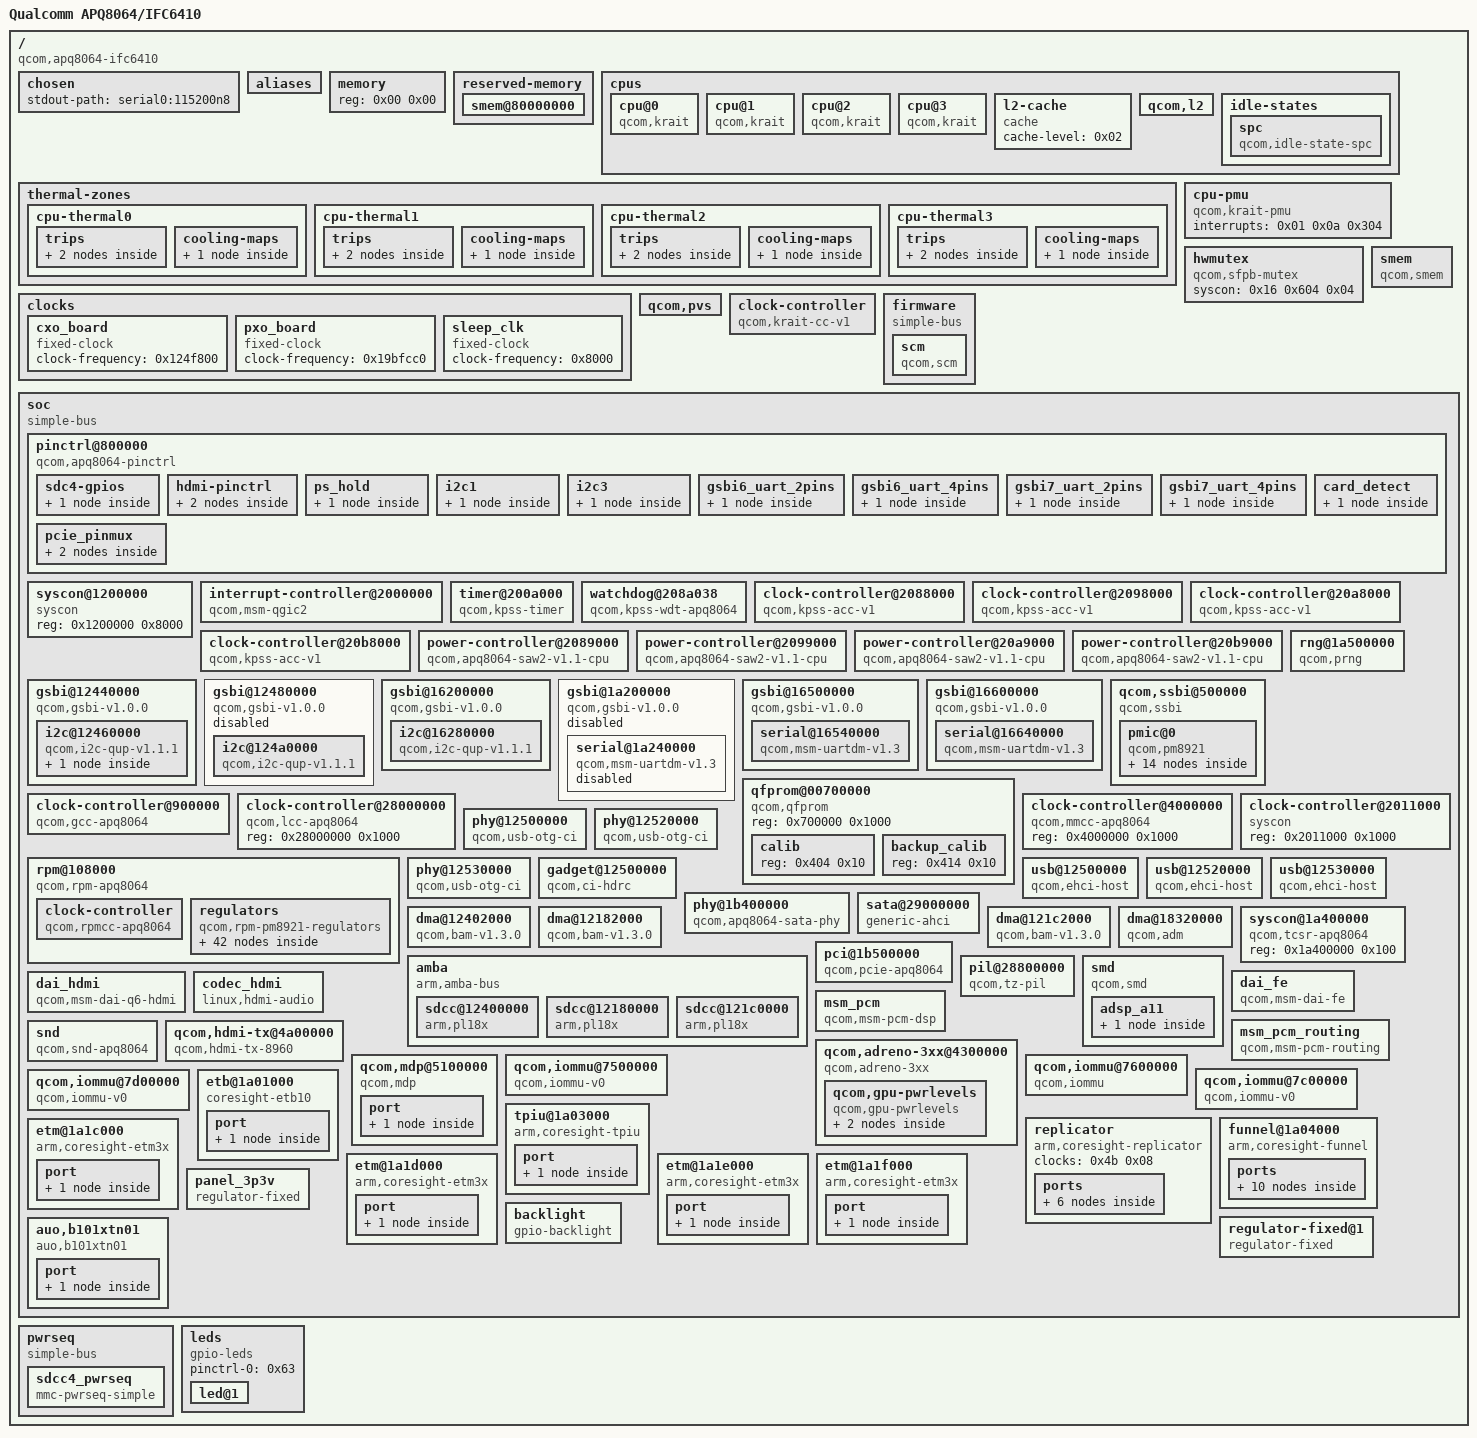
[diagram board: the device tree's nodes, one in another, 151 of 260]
/dts-v1/;

/ {
	#address-cells = <0x01>;
	#size-cells = <0x01>;
	model = "Qualcomm APQ8064/IFC6410";
	compatible = "qcom,apq8064-ifc6410\0qcom,apq8064";
	interrupt-parent = <0x01>;

	chosen {
		stdout-path = "serial0:115200n8";
	};

	aliases {
		serial0 = "/soc/gsbi@16600000/serial@16640000";
		serial1 = "/soc/gsbi@16500000/serial@16540000";
	};

	memory {
		device_type = "memory";
		reg = <0x00 0x00>;
	};

	reserved-memory {
		#address-cells = <0x01>;
		#size-cells = <0x01>;
		ranges;

		smem@80000000 {
			reg = <0x80000000 0x200000>;
			no-map;
			linux,phandle = <0x17>;
			phandle = <0x17>;
		};
	};

	cpus {
		#address-cells = <0x01>;
		#size-cells = <0x00>;

		cpu@0 {
			compatible = "qcom,krait";
			enable-method = "qcom,kpss-acc-v1";
			device_type = "cpu";
			reg = <0x00>;
			next-level-cache = <0x02>;
			qcom,acc = <0x03>;
			qcom,saw = <0x04>;
			cpu-idle-states = <0x05>;
			clocks = <0x06 0x00 0x06 0x04>;
			clock-names = "cpu\0l2";
			clock-latency = <0x186a0>;
			cooling-min-level = <0x00>;
			cooling-max-level = <0x07>;
			#cooling-cells = <0x02>;
			cpu-supply = <0x04>;
			linux,phandle = <0x0f>;
			phandle = <0x0f>;
		};

		cpu@1 {
			compatible = "qcom,krait";
			enable-method = "qcom,kpss-acc-v1";
			device_type = "cpu";
			reg = <0x01>;
			next-level-cache = <0x02>;
			qcom,acc = <0x07>;
			qcom,saw = <0x08>;
			cpu-idle-states = <0x05>;
			clocks = <0x06 0x01 0x06 0x04>;
			clock-names = "cpu\0l2";
			clock-latency = <0x186a0>;
			cooling-min-level = <0x00>;
			cooling-max-level = <0x07>;
			#cooling-cells = <0x02>;
			cpu-supply = <0x08>;
			linux,phandle = <0x11>;
			phandle = <0x11>;
		};

		cpu@2 {
			compatible = "qcom,krait";
			enable-method = "qcom,kpss-acc-v1";
			device_type = "cpu";
			reg = <0x02>;
			next-level-cache = <0x02>;
			qcom,acc = <0x09>;
			qcom,saw = <0x0a>;
			cpu-idle-states = <0x05>;
			clocks = <0x06 0x02 0x06 0x04>;
			clock-names = "cpu\0l2";
			clock-latency = <0x186a0>;
			cooling-min-level = <0x00>;
			cooling-max-level = <0x07>;
			#cooling-cells = <0x02>;
			cpu-supply = <0x0a>;
			linux,phandle = <0x13>;
			phandle = <0x13>;
		};

		cpu@3 {
			compatible = "qcom,krait";
			enable-method = "qcom,kpss-acc-v1";
			device_type = "cpu";
			reg = <0x03>;
			next-level-cache = <0x02>;
			qcom,acc = <0x0b>;
			qcom,saw = <0x0c>;
			cpu-idle-states = <0x05>;
			clocks = <0x06 0x03 0x06 0x04>;
			clock-names = "cpu\0l2";
			clock-latency = <0x186a0>;
			cooling-min-level = <0x00>;
			cooling-max-level = <0x07>;
			#cooling-cells = <0x02>;
			cpu-supply = <0x0c>;
			linux,phandle = <0x15>;
			phandle = <0x15>;
		};

		l2-cache {
			compatible = "cache";
			cache-level = <0x02>;
			linux,phandle = <0x02>;
			phandle = <0x02>;
		};

		qcom,l2 {
			qcom,l2-rates = <0x16e36000 0x39ef8b00 0x46cf7100>;
		};

		idle-states {

			spc {
				compatible = "qcom,idle-state-spc\0arm,idle-state";
				entry-latency-us = <0x190>;
				exit-latency-us = <0x384>;
				min-residency-us = <0xbb8>;
				linux,phandle = <0x05>;
				phandle = <0x05>;
			};
		};
	};

	thermal-zones {

		cpu-thermal0 {
			polling-delay-passive = <0xfa>;
			polling-delay = <0x3e8>;
			thermal-sensors = <0x0d 0x07>;

			trips {

				trip@0 {
					temperature = <0x124f8>;
					hysteresis = <0x7d0>;
					type = "passive";
					linux,phandle = <0x0e>;
					phandle = <0x0e>;
				};

				trip@1 {
					temperature = <0x17318>;
					hysteresis = <0x7d0>;
					type = "critical";
				};
			};

			cooling-maps {

				map0 {
					trip = <0x0e>;
					cooling-device = <0x0f 0xffffffff 0xffffffff>;
				};
			};
		};

		cpu-thermal1 {
			polling-delay-passive = <0xfa>;
			polling-delay = <0x3e8>;
			thermal-sensors = <0x0d 0x08>;

			trips {

				trip@0 {
					temperature = <0x124f8>;
					hysteresis = <0x7d0>;
					type = "passive";
					linux,phandle = <0x10>;
					phandle = <0x10>;
				};

				trip@1 {
					temperature = <0x17318>;
					hysteresis = <0x7d0>;
					type = "critical";
				};
			};

			cooling-maps {

				map0 {
					trip = <0x10>;
					cooling-device = <0x11 0xffffffff 0xffffffff>;
				};
			};
		};

		cpu-thermal2 {
			polling-delay-passive = <0xfa>;
			polling-delay = <0x3e8>;
			thermal-sensors = <0x0d 0x09>;

			trips {

				trip@0 {
					temperature = <0x124f8>;
					hysteresis = <0x7d0>;
					type = "passive";
					linux,phandle = <0x12>;
					phandle = <0x12>;
				};

				trip@1 {
					temperature = <0x17318>;
					hysteresis = <0x7d0>;
					type = "critical";
				};
			};

			cooling-maps {

				map0 {
					trip = <0x12>;
					cooling-device = <0x13 0xffffffff 0xffffffff>;
				};
			};
		};

		cpu-thermal3 {
			polling-delay-passive = <0xfa>;
			polling-delay = <0x3e8>;
			thermal-sensors = <0x0d 0x0a>;

			trips {

				trip@0 {
					temperature = <0x124f8>;
					hysteresis = <0x7d0>;
					type = "passive";
					linux,phandle = <0x14>;
					phandle = <0x14>;
				};

				trip@1 {
					temperature = <0x17318>;
					hysteresis = <0x7d0>;
					type = "critical";
				};
			};

			cooling-maps {

				map0 {
					trip = <0x14>;
					cooling-device = <0x15 0xffffffff 0xffffffff>;
				};
			};
		};
	};

	cpu-pmu {
		compatible = "qcom,krait-pmu";
		interrupts = <0x01 0x0a 0x304>;
	};

	clocks {

		cxo_board {
			compatible = "fixed-clock";
			#clock-cells = <0x00>;
			clock-frequency = <0x124f800>;
		};

		pxo_board {
			compatible = "fixed-clock";
			#clock-cells = <0x00>;
			clock-frequency = <0x19bfcc0>;
		};

		sleep_clk {
			compatible = "fixed-clock";
			#clock-cells = <0x00>;
			clock-frequency = <0x8000>;
			linux,phandle = <0x1a>;
			phandle = <0x1a>;
		};
	};

	hwmutex {
		compatible = "qcom,sfpb-mutex";
		syscon = <0x16 0x604 0x04>;
		#hwlock-cells = <0x01>;
		linux,phandle = <0x18>;
		phandle = <0x18>;
	};

	smem {
		compatible = "qcom,smem";
		memory-region = <0x17>;
		hwlocks = <0x18 0x03>;
	};

	qcom,pvs {
		qcom,pvs-format-a;
		qcom,speed0-pvs0-bin-v0 = <0x16e36000 0xe7ef0 0x1cf7c580 0xee098 0x2367b880 0xf4240 0x29d7ab80 0xfa3e8 0x30479e80 0x106738 0x36b79180 0x10c8e0 0x3d278480 0x112a88 0x405f7e00 0x11edd8 0x43977780 0x11edd8 0x46cf7100 0x124f80 0x4a076a80 0x124f80 0x4d3f6400 0x12b128 0x50775d80 0x12b128 0x53af5700 0x12e1fc 0x56e75080 0x12e1fc 0x5a1f4a00 0x1312d0>;
		qcom,speed0-pvs1-bin-v0 = <0x16e36000 0xdbba0 0x1cf7c580 0xe1d48 0x2367b880 0xe7ef0 0x29d7ab80 0xee098 0x30479e80 0xfa3e8 0x36b79180 0x100590 0x3d278480 0x106738 0x405f7e00 0x112a88 0x43977780 0x112a88 0x46cf7100 0x118c30 0x4a076a80 0x118c30 0x4d3f6400 0x11edd8 0x50775d80 0x11edd8 0x53af5700 0x121eac 0x56e75080 0x121eac 0x5a1f4a00 0x124f80>;
		qcom,speed0-pvs3-bin-v0 = <0x16e36000 0xcf850 0x1cf7c580 0xd59f8 0x2367b880 0xdbba0 0x29d7ab80 0xe1d48 0x30479e80 0xee098 0x36b79180 0xf4240 0x3d278480 0xfa3e8 0x405f7e00 0x106738 0x43977780 0x106738 0x46cf7100 0x10c8e0 0x4a076a80 0x10c8e0 0x4d3f6400 0x112a88 0x50775d80 0x112a88 0x53af5700 0x115b5c 0x56e75080 0x115b5c 0x5a1f4a00 0x118c30>;
		qcom,speed0-pvs4-bin-v0 = <0x16e36000 0xcf850 0x1cf7c580 0xd59f8 0x2367b880 0xdbba0 0x29d7ab80 0xe1d48 0x30479e80 0xeafc4 0x36b79180 0xee098 0x3d278480 0xf4240 0x405f7e00 0x100590 0x43977780 0x100590 0x46cf7100 0x106738 0x4a076a80 0x106738 0x4d3f6400 0x10c8e0 0x50775d80 0x10c8e0 0x53af5700 0x10f9b4 0x56e75080 0x10f9b4 0x5a1f4a00 0x112a88>;
		qcom,speed1-pvs0-bin-v0 = <0x16e36000 0xe7ef0 0x1cf7c580 0xe7ef0 0x2367b880 0xe7ef0 0x29d7ab80 0xeafc4 0x30479e80 0xf4240 0x36b79180 0xfa3e8 0x3d278480 0xfd4bc 0x43977780 0x106738 0x4a076a80 0x10980c 0x50775d80 0x112a88 0x56e75080 0x118c30 0x5d574380 0x11edd8 0x63c73680 0x12b128 0x66ff3000 0x1312d0>;
		qcom,speed1-pvs1-bin-v0 = <0x16e36000 0xe7ef0 0x1cf7c580 0xe7ef0 0x2367b880 0xe7ef0 0x29d7ab80 0xeafc4 0x30479e80 0xee098 0x36b79180 0xf4240 0x3d278480 0xf7314 0x43977780 0xfd4bc 0x4a076a80 0x100590 0x50775d80 0x10980c 0x56e75080 0x10f9b4 0x5d574380 0x118c30 0x63c73680 0x121eac 0x66ff3000 0x124f80>;
		qcom,speed1-pvs2-bin-v0 = <0x16e36000 0xe1d48 0x1cf7c580 0xe1d48 0x2367b880 0xe1d48 0x29d7ab80 0xe1d48 0x30479e80 0xe4e1c 0x36b79180 0xe7ef0 0x3d278480 0xee098 0x43977780 0xf4240 0x4a076a80 0xf7314 0x50775d80 0xfd4bc 0x56e75080 0x106738 0x5d574380 0x10c8e0 0x63c73680 0x115b5c 0x66ff3000 0x11bd04>;
		qcom,speed1-pvs3-bin-v0 = <0x16e36000 0xdbba0 0x1cf7c580 0xdbba0 0x2367b880 0xdbba0 0x29d7ab80 0xdbba0 0x30479e80 0xdbba0 0x36b79180 0xe1d48 0x3d278480 0xe7ef0 0x43977780 0xee098 0x4a076a80 0xf116c 0x50775d80 0xf4240 0x56e75080 0xfd4bc 0x5d574380 0x103664 0x63c73680 0x10c8e0 0x66ff3000 0x112a88>;
		qcom,speed1-pvs4-bin-v0 = <0x16e36000 0xd59f8 0x1cf7c580 0xd59f8 0x2367b880 0xd59f8 0x29d7ab80 0xd59f8 0x30479e80 0xd8acc 0x36b79180 0xdbba0 0x3d278480 0xe1d48 0x43977780 0xe7ef0 0x4a076a80 0xeafc4 0x50775d80 0xee098 0x56e75080 0xf4240 0x5d574380 0xfd4bc 0x63c73680 0x106738 0x66ff3000 0x10c8e0>;
		qcom,speed1-pvs5-bin-v0 = <0x16e36000 0xd59f8 0x1cf7c580 0xd59f8 0x2367b880 0xd59f8 0x29d7ab80 0xd59f8 0x30479e80 0xd8acc 0x36b79180 0xdbba0 0x3d278480 0xe1d48 0x43977780 0xe4e1c 0x4a076a80 0xe7ef0 0x50775d80 0xeafc4 0x56e75080 0xf116c 0x5d574380 0xf7314 0x63c73680 0x100590 0x66ff3000 0x106738>;
		qcom,speed1-pvs6-bin-v0 = <0x16e36000 0xd59f8 0x1cf7c580 0xd59f8 0x2367b880 0xd59f8 0x29d7ab80 0xd59f8 0x30479e80 0xd8acc 0x36b79180 0xdbba0 0x3d278480 0xe1d48 0x43977780 0xe4e1c 0x4a076a80 0xe7ef0 0x50775d80 0xeafc4 0x56e75080 0xee098 0x5d574380 0xf4240 0x63c73680 0xfa3e8 0x66ff3000 0x100590>;
		qcom,speed2-pvs0-bin-v0 = <0x16e36000 0xe7ef0 0x1cf7c580 0xe7ef0 0x2367b880 0xe7ef0 0x29d7ab80 0xe7ef0 0x30479e80 0xeafc4 0x36b79180 0xee098 0x3d278480 0xf4240 0x43977780 0xfa3e8 0x4a076a80 0xfd4bc 0x50775d80 0x103664 0x56e75080 0x10c8e0 0x5d574380 0x112a88 0x63c73680 0x11edd8 0x6a372980 0x12b128 0x70a71c80 0x13a54c>;
		qcom,speed2-pvs1-bin-v0 = <0x16e36000 0xe1d48 0x1cf7c580 0xe1d48 0x2367b880 0xe1d48 0x29d7ab80 0xe1d48 0x30479e80 0xe4e1c 0x36b79180 0xe7ef0 0x3d278480 0xee098 0x43977780 0xf4240 0x4a076a80 0xf7314 0x50775d80 0xfd4bc 0x56e75080 0x106738 0x5d574380 0x10c8e0 0x63c73680 0x115b5c 0x6a372980 0x121eac 0x70a71c80 0x1312d0>;
		qcom,speed2-pvs2-bin-v0 = <0x16e36000 0xdbba0 0x1cf7c580 0xdbba0 0x2367b880 0xdbba0 0x29d7ab80 0xdbba0 0x30479e80 0xdec74 0x36b79180 0xe1d48 0x3d278480 0xe7ef0 0x43977780 0xee098 0x4a076a80 0xf116c 0x50775d80 0xf7314 0x56e75080 0x100590 0x5d574380 0x106738 0x63c73680 0x10f9b4 0x6a372980 0x11bd04 0x70a71c80 0x128054>;
		qcom,speed2-pvs3-bin-v0 = <0x16e36000 0xdbba0 0x1cf7c580 0xdbba0 0x2367b880 0xdbba0 0x29d7ab80 0xdbba0 0x30479e80 0xdbba0 0x36b79180 0xdec74 0x3d278480 0xe4e1c 0x43977780 0xeafc4 0x4a076a80 0xee098 0x50775d80 0xf4240 0x56e75080 0xfa3e8 0x5d574380 0x100590 0x63c73680 0x10980c 0x6a372980 0x115b5c 0x70a71c80 0x11edd8>;
		qcom,speed2-pvs4-bin-v0 = <0x16e36000 0xd59f8 0x1cf7c580 0xd59f8 0x2367b880 0xd59f8 0x29d7ab80 0xd59f8 0x30479e80 0xd8acc 0x36b79180 0xdbba0 0x3d278480 0xe1d48 0x43977780 0xe7ef0 0x4a076a80 0xeafc4 0x50775d80 0xee098 0x56e75080 0xf4240 0x5d574380 0xfd4bc 0x63c73680 0x106738 0x6a372980 0x10f9b4 0x70a71c80 0x118c30>;
		qcom,speed2-pvs5-bin-v0 = <0x16e36000 0xd59f8 0x1cf7c580 0xd59f8 0x2367b880 0xd59f8 0x29d7ab80 0xd59f8 0x30479e80 0xd8acc 0x36b79180 0xdbba0 0x3d278480 0xe1d48 0x43977780 0xe4e1c 0x4a076a80 0xe7ef0 0x50775d80 0xeafc4 0x56e75080 0xf116c 0x5d574380 0xf7314 0x63c73680 0x100590 0x6a372980 0x10980c 0x70a71c80 0x112a88>;
		qcom,speed2-pvs6-bin-v0 = <0x16e36000 0xd59f8 0x1cf7c580 0xd59f8 0x2367b880 0xd59f8 0x29d7ab80 0xd59f8 0x30479e80 0xd8acc 0x36b79180 0xdbba0 0x3d278480 0xe1d48 0x43977780 0xe4e1c 0x4a076a80 0xe7ef0 0x50775d80 0xeafc4 0x56e75080 0xee098 0x5d574380 0xf4240 0x63c73680 0xfa3e8 0x6a372980 0x103664 0x70a71c80 0x10c8e0>;
		qcom,speed14-pvs0-bin-v0 = <0x16e36000 0xe7ef0 0x1cf7c580 0xe7ef0 0x2367b880 0xe7ef0 0x29d7ab80 0xeafc4 0x30479e80 0xf4240 0x36b79180 0xfa3e8 0x3d278480 0xfd4bc 0x43977780 0x106738 0x4a076a80 0x10980c 0x50775d80 0x112a88 0x56e75080 0x118c30 0x5a1f4a00 0x11bd04>;
		qcom,speed14-pvs1-bin-v0 = <0x16e36000 0xe7ef0 0x1cf7c580 0xe7ef0 0x2367b880 0xe7ef0 0x29d7ab80 0xeafc4 0x30479e80 0xee098 0x36b79180 0xf4240 0x3d278480 0xf7314 0x43977780 0xfd4bc 0x4a076a80 0x100590 0x50775d80 0x10980c 0x56e75080 0x10f9b4 0x5a1f4a00 0x112a88>;
		qcom,speed14-pvs2-bin-v0 = <0x16e36000 0xe1d48 0x1cf7c580 0xe1d48 0x2367b880 0xe1d48 0x29d7ab80 0xe1d48 0x30479e80 0xe4e1c 0x36b79180 0xe7ef0 0x3d278480 0xee098 0x43977780 0xf4240 0x4a076a80 0xf7314 0x50775d80 0xfd4bc 0x56e75080 0x106738 0x5a1f4a00 0x10980c>;
		qcom,speed14-pvs3-bin-v0 = <0x16e36000 0xdbba0 0x1cf7c580 0xdbba0 0x2367b880 0xdbba0 0x29d7ab80 0xdbba0 0x30479e80 0xdbba0 0x36b79180 0xe1d48 0x3d278480 0xe7ef0 0x43977780 0xee098 0x4a076a80 0xf116c 0x50775d80 0xf4240 0x56e75080 0xfd4bc 0x5a1f4a00 0x100590>;
		qcom,speed14-pvs4-bin-v0 = <0x16e36000 0xd59f8 0x1cf7c580 0xd59f8 0x2367b880 0xd59f8 0x29d7ab80 0xd59f8 0x30479e80 0xd8acc 0x36b79180 0xdbba0 0x3d278480 0xe1d48 0x43977780 0xe7ef0 0x4a076a80 0xeafc4 0x50775d80 0xee098 0x56e75080 0xf4240 0x5a1f4a00 0xf7314>;
		qcom,speed14-pvs5-bin-v0 = <0x16e36000 0xd59f8 0x1cf7c580 0xd59f8 0x2367b880 0xd59f8 0x29d7ab80 0xd59f8 0x30479e80 0xd8acc 0x36b79180 0xdbba0 0x3d278480 0xe1d48 0x43977780 0xe4e1c 0x4a076a80 0xe7ef0 0x50775d80 0xeafc4 0x56e75080 0xf116c 0x5a1f4a00 0xf4240>;
		qcom,speed14-pvs6-bin-v0 = <0x16e36000 0xd59f8 0x1cf7c580 0xd59f8 0x2367b880 0xd59f8 0x29d7ab80 0xd59f8 0x30479e80 0xd8acc 0x36b79180 0xdbba0 0x3d278480 0xe1d48 0x43977780 0xe4e1c 0x4a076a80 0xe7ef0 0x50775d80 0xeafc4 0x56e75080 0xee098 0x5a1f4a00 0xf116c>;
	};

	clock-controller {
		compatible = "qcom,krait-cc-v1";
		#clock-cells = <0x01>;
		linux,phandle = <0x06>;
		phandle = <0x06>;
	};

	firmware {
		compatible = "simple-bus";

		scm {
			compatible = "qcom,scm";
		};
	};

	soc {
		#address-cells = <0x01>;
		#size-cells = <0x01>;
		ranges;
		compatible = "simple-bus";

		pinctrl@800000 {
			compatible = "qcom,apq8064-pinctrl";
			reg = <0x800000 0x4000>;
			gpio-controller;
			#gpio-cells = <0x02>;
			interrupt-controller;
			#interrupt-cells = <0x02>;
			interrupts = <0x00 0x10 0x04>;
			pinctrl-names = "default";
			pinctrl-0 = <0x19>;
			linux,phandle = <0x21>;
			phandle = <0x21>;

			sdc4-gpios {
				linux,phandle = <0x37>;
				phandle = <0x37>;

				pios {
					pins = "gpio63\0gpio64\0gpio65\0gpio66\0gpio67\0gpio68";
					function = "sdc4";
				};
			};

			hdmi-pinctrl {
				linux,phandle = <0x40>;
				phandle = <0x40>;

				mux1 {
					pins = "gpio69\0gpio70\0gpio71";
					function = "hdmi";
					bias-pull-up;
					drive-strength = <0x02>;
				};

				mux2 {
					pins = "gpio72";
					function = "hdmi";
					bias-pull-down;
					drive-strength = <0x10>;
				};
			};

			ps_hold {
				linux,phandle = <0x19>;
				phandle = <0x19>;

				mux {
					pins = "gpio78";
					function = "ps_hold";
				};
			};

			i2c1 {
				linux,phandle = <0x1c>;
				phandle = <0x1c>;

				mux {
					pins = "gpio20\0gpio21";
					function = "gsbi1";
				};
			};

			i2c3 {
				linux,phandle = <0x1d>;
				phandle = <0x1d>;

				mux {
					pins = "gpio8\0gpio9";
					function = "gsbi3";
				};
			};

			gsbi6_uart_2pins {

				mux {
					pins = "gpio14\0gpio15";
					function = "gsbi6";
				};
			};

			gsbi6_uart_4pins {
				linux,phandle = <0x1f>;
				phandle = <0x1f>;

				mux {
					pins = "gpio14\0gpio15\0gpio16\0gpio17";
					function = "gsbi6";
				};
			};

			gsbi7_uart_2pins {
				linux,phandle = <0x20>;
				phandle = <0x20>;

				mux {
					pins = "gpio82\0gpio83";
					function = "gsbi7";
				};
			};

			gsbi7_uart_4pins {

				mux {
					pins = "gpio82\0gpio83\0gpio84\0gpio85";
					function = "gsbi7";
				};
			};

			card_detect {
				linux,phandle = <0x35>;
				phandle = <0x35>;

				mux {
					pins = "gpio26";
					function = "gpio";
					bias-disable;
				};
			};

			pcie_pinmux {
				linux,phandle = <0x3c>;
				phandle = <0x3c>;

				mux {
					pins = "gpio27";
					function = "gpio";
				};

				conf {
					pins = "gpio27";
					drive-strength = <0x0c>;
					bias-disable;
				};
			};
		};

		syscon@1200000 {
			compatible = "syscon";
			reg = <0x1200000 0x8000>;
			linux,phandle = <0x16>;
			phandle = <0x16>;
		};

		interrupt-controller@2000000 {
			compatible = "qcom,msm-qgic2";
			interrupt-controller;
			#interrupt-cells = <0x03>;
			reg = <0x2000000 0x1000 0x2002000 0x1000>;
			linux,phandle = <0x01>;
			phandle = <0x01>;
		};

		timer@200a000 {
			compatible = "qcom,kpss-timer\0qcom,msm-timer";
			interrupts = <0x01 0x01 0x301 0x01 0x02 0x301 0x01 0x03 0x301>;
			reg = <0x200a000 0x100>;
			clock-frequency = <0x19bfcc0 0x8000>;
			cpu-offset = <0x80000>;
		};

		watchdog@208a038 {
			compatible = "qcom,kpss-wdt-apq8064";
			reg = <0x208a038 0x40>;
			clocks = <0x1a>;
			timeout-sec = <0x0a>;
		};

		clock-controller@2088000 {
			compatible = "qcom,kpss-acc-v1";
			reg = <0x2088000 0x1000 0x2008000 0x1000>;
			clock-output-names = "acpu0_aux";
			linux,phandle = <0x03>;
			phandle = <0x03>;
		};

		clock-controller@2098000 {
			compatible = "qcom,kpss-acc-v1";
			reg = <0x2098000 0x1000 0x2008000 0x1000>;
			clock-output-names = "acpu1_aux";
			linux,phandle = <0x07>;
			phandle = <0x07>;
		};

		clock-controller@20a8000 {
			compatible = "qcom,kpss-acc-v1";
			reg = <0x20a8000 0x1000 0x2008000 0x1000>;
			clock-output-names = "acpu2_aux";
			linux,phandle = <0x09>;
			phandle = <0x09>;
		};

		clock-controller@20b8000 {
			compatible = "qcom,kpss-acc-v1";
			reg = <0x20b8000 0x1000 0x2008000 0x1000>;
			clock-output-names = "acpu3_aux";
			linux,phandle = <0x0b>;
			phandle = <0x0b>;
		};

		power-controller@2089000 {
			compatible = "qcom,apq8064-saw2-v1.1-cpu\0qcom,saw2";
			reg = <0x2089000 0x1000 0x2009000 0x1000>;
			regulator;
			regulator-name = "krait0";
			regulator-always-on;
			regulator-min-microvolt = <0xc96a8>;
			regulator-max-microvolt = <0x1312d0>;
			linux,phandle = <0x04>;
			phandle = <0x04>;
		};

		power-controller@2099000 {
			compatible = "qcom,apq8064-saw2-v1.1-cpu\0qcom,saw2";
			reg = <0x2099000 0x1000 0x2009000 0x1000>;
			regulator;
			regulator-name = "krait1";
			regulator-always-on;
			regulator-min-microvolt = <0xc96a8>;
			regulator-max-microvolt = <0x1312d0>;
			linux,phandle = <0x08>;
			phandle = <0x08>;
		};

		power-controller@20a9000 {
			compatible = "qcom,apq8064-saw2-v1.1-cpu\0qcom,saw2";
			reg = <0x20a9000 0x1000 0x2009000 0x1000>;
			regulator;
			regulator-name = "krait2";
			regulator-always-on;
			regulator-min-microvolt = <0xc96a8>;
			regulator-max-microvolt = <0x1312d0>;
			linux,phandle = <0x0a>;
			phandle = <0x0a>;
		};

		power-controller@20b9000 {
			compatible = "qcom,apq8064-saw2-v1.1-cpu\0qcom,saw2";
			reg = <0x20b9000 0x1000 0x2009000 0x1000>;
			regulator;
			regulator-name = "krait3";
			regulator-always-on;
			regulator-min-microvolt = <0xc96a8>;
			regulator-max-microvolt = <0x1312d0>;
			linux,phandle = <0x0c>;
			phandle = <0x0c>;
		};

		gsbi@12440000 {
			status = "okay";
			compatible = "qcom,gsbi-v1.0.0";
			cell-index = <0x01>;
			reg = <0x12440000 0x100>;
			clocks = <0x0d 0x93>;
			clock-names = "iface";
			#address-cells = <0x01>;
			#size-cells = <0x01>;
			ranges;
			syscon-tcsr = <0x1b>;
			qcom,mode = <0x02>;

			i2c@12460000 {
				compatible = "qcom,i2c-qup-v1.1.1";
				pinctrl-0 = <0x1c>;
				pinctrl-names = "default";
				reg = <0x12460000 0x1000>;
				interrupts = <0x00 0xc2 0x00>;
				clocks = <0x0d 0xb8 0x0d 0x93>;
				clock-names = "core\0iface";
				#address-cells = <0x01>;
				#size-cells = <0x00>;
				status = "okay";
				clock-frequency = <0x30d40>;

				eeprom@52 {
					compatible = "atmel,24c128";
					reg = <0x52>;
					pagesize = <0x20>;
				};
			};
		};

		gsbi@12480000 {
			status = "disabled";
			compatible = "qcom,gsbi-v1.0.0";
			cell-index = <0x02>;
			reg = <0x12480000 0x100>;
			clocks = <0x0d 0x94>;
			clock-names = "iface";
			#address-cells = <0x01>;
			#size-cells = <0x01>;
			ranges;
			syscon-tcsr = <0x1b>;

			i2c@124a0000 {
				compatible = "qcom,i2c-qup-v1.1.1";
				reg = <0x124a0000 0x1000>;
				interrupts = <0x00 0xc4 0x00>;
				clocks = <0x0d 0xba 0x0d 0x94>;
				clock-names = "core\0iface";
				#address-cells = <0x01>;
				#size-cells = <0x00>;
			};
		};

		gsbi@16200000 {
			status = "okay";
			compatible = "qcom,gsbi-v1.0.0";
			cell-index = <0x03>;
			reg = <0x16200000 0x100>;
			clocks = <0x0d 0x95>;
			clock-names = "iface";
			#address-cells = <0x01>;
			#size-cells = <0x01>;
			ranges;
			qcom,mode = <0x02>;

			i2c@16280000 {
				compatible = "qcom,i2c-qup-v1.1.1";
				pinctrl-0 = <0x1d>;
				pinctrl-names = "default";
				reg = <0x16280000 0x1000>;
				interrupts = <0x00 0x97 0x00>;
				clocks = <0x0d 0xbc 0x0d 0x95>;
				clock-names = "core\0iface";
				status = "okay";
				linux,phandle = <0x5d>;
				phandle = <0x5d>;
			};
		};

		gsbi@1a200000 {
			status = "disabled";
			compatible = "qcom,gsbi-v1.0.0";
			cell-index = <0x05>;
			reg = <0x1a200000 0x03>;
			clocks = <0x0d 0x97>;
			clock-names = "iface";
			#address-cells = <0x01>;
			#size-cells = <0x01>;
			ranges;

			serial@1a240000 {
				compatible = "qcom,msm-uartdm-v1.3\0qcom,msm-uartdm";
				reg = <0x1a240000 0x100 0x1a200000 0x03>;
				interrupts = <0x00 0x9a 0x00>;
				clocks = <0x0d 0xa8 0x0d 0x97>;
				clock-names = "core\0iface";
				status = "disabled";
			};
		};

		gsbi@16500000 {
			status = "ok";
			compatible = "qcom,gsbi-v1.0.0";
			cell-index = <0x06>;
			reg = <0x16500000 0x03>;
			clocks = <0x0d 0x98>;
			clock-names = "iface";
			#address-cells = <0x01>;
			#size-cells = <0x01>;
			ranges;
			syscon-tcsr = <0x1b>;
			qcom,mode = <0x04>;

			serial@16540000 {
				compatible = "qcom,msm-uartdm-v1.3\0qcom,msm-uartdm";
				reg = <0x16540000 0x100 0x16500000 0x03>;
				interrupts = <0x00 0x9c 0x00>;
				clocks = <0x0d 0xaa 0x0d 0x98>;
				clock-names = "core\0iface";
				qcom,rx-crci = <0x0b>;
				qcom,tx-crci = <0x06>;
				dmas = <0x1e 0x06 0x1e 0x07>;
				dma-names = "rx\0tx";
				status = "ok";
				pinctrl-names = "default";
				pinctrl-0 = <0x1f>;
			};
		};

		gsbi@16600000 {
			status = "ok";
			compatible = "qcom,gsbi-v1.0.0";
			cell-index = <0x07>;
			reg = <0x16600000 0x100>;
			clocks = <0x0d 0x99>;
			clock-names = "iface";
			#address-cells = <0x01>;
			#size-cells = <0x01>;
			ranges;
			syscon-tcsr = <0x1b>;
			qcom,mode = <0x06>;

			serial@16640000 {
				compatible = "qcom,msm-uartdm-v1.3\0qcom,msm-uartdm";
				reg = <0x16640000 0x1000 0x16600000 0x1000>;
				interrupts = <0x00 0x9e 0x00>;
				clocks = <0x0d 0xac 0x0d 0x99>;
				clock-names = "core\0iface";
				status = "ok";
				pinctrl-names = "default";
				pinctrl-0 = <0x20>;
			};
		};

		rng@1a500000 {
			compatible = "qcom,prng";
			reg = <0x1a500000 0x200>;
			clocks = <0x0d 0x108>;
			clock-names = "core";
		};

		qcom,ssbi@500000 {
			compatible = "qcom,ssbi";
			reg = <0x500000 0x1000>;
			qcom,controller-type = "pmic-arbiter";

			pmic@0 {
				compatible = "qcom,pm8921";
				interrupt-parent = <0x21>;
				interrupts = <0x4a 0x08>;
				#interrupt-cells = <0x02>;
				interrupt-controller;
				#address-cells = <0x01>;
				#size-cells = <0x00>;
				linux,phandle = <0x22>;
				phandle = <0x22>;

				gpio@150 {
					compatible = "qcom,pm8921-gpio\0qcom,ssbi-gpio";
					reg = <0x150>;
					interrupts = <0xc0 0x01 0xc1 0x01 0xc2 0x01 0xc3 0x01 0xc4 0x01 0xc5 0x01 0xc6 0x01 0xc7 0x01 0xc8 0x01 0xc9 0x01 0xca 0x01 0xcb 0x01 0xcc 0x01 0xcd 0x01 0xce 0x01 0xcf 0x01 0xd0 0x01 0xd1 0x01 0xd2 0x01 0xd3 0x01 0xd4 0x01 0xd5 0x01 0xd6 0x01 0xd7 0x01 0xd8 0x01 0xd9 0x01 0xda 0x01 0xdb 0x01 0xdc 0x01 0xdd 0x01 0xde 0x01 0xdf 0x01 0xe0 0x01 0xe1 0x01 0xe2 0x01 0xe3 0x01 0xe4 0x01 0xe5 0x01 0xe6 0x01 0xe7 0x01 0xe8 0x01 0xe9 0x01 0xea 0x01 0xeb 0x01>;
					gpio-controller;
					#gpio-cells = <0x02>;
					linux,phandle = <0x5b>;
					phandle = <0x5b>;

					pwm-bl-gpios {
						linux,phandle = <0x5c>;
						phandle = <0x5c>;

						pios {
							pins = "gpio26";
							bias-disable;
							function = "normal";
							qcom,drive-strength = <0x01>;
							power-source = <0x02>;
						};
					};

					disp-en-gpios {
						linux,phandle = <0x5a>;
						phandle = <0x5a>;

						pios {
							pins = "gpio36";
							bias-disable;
							function = "normal";
							qcom,drive-strength = <0x01>;
							power-source = <0x02>;
						};
					};

					wlan-gpios {
						linux,phandle = <0x61>;
						phandle = <0x61>;

						pios {
							pins = "gpio43";
							function = "normal";
							bias-disable;
							power-source = <0x02>;
						};
					};

					bt-gpio {
						linux,phandle = <0x62>;
						phandle = <0x62>;

						pios {
							pins = "gpio44";
							function = "normal";
							bias-disable;
							power-source = <0x02>;
						};
					};

					nled {
						linux,phandle = <0x63>;
						phandle = <0x63>;

						pios {
							pins = "gpio18";
							function = "normal";
							bias-disable;
							power-source = <0x02>;
						};
					};
				};

				mpps@50 {
					compatible = "qcom,pm8921-mpp\0qcom,ssbi-mpp";
					reg = <0x50>;
					gpio-controller;
					#gpio-cells = <0x02>;
					interrupts = <0x80 0x01 0x81 0x01 0x82 0x01 0x83 0x01 0x84 0x01 0x85 0x01 0x86 0x01 0x87 0x01 0x88 0x01 0x89 0x01 0x8a 0x01 0x8b 0x01>;
				};

				rtc@11d {
					compatible = "qcom,pm8921-rtc";
					interrupt-parent = <0x22>;
					interrupts = <0x27 0x01>;
					reg = <0x11d>;
					allow-set-time;
				};

				pwrkey@1c {
					compatible = "qcom,pm8921-pwrkey";
					reg = <0x1c>;
					interrupt-parent = <0x22>;
					interrupts = <0x32 0x01 0x33 0x01>;
					debounce = <0x3d09>;
					pull-up;
				};
			};
		};

		qfprom@00700000 {
			compatible = "qcom,qfprom";
			reg = <0x700000 0x1000>;
			#address-cells = <0x01>;
			#size-cells = <0x01>;
			ranges;

			calib {
				reg = <0x404 0x10>;
				linux,phandle = <0x23>;
				phandle = <0x23>;
			};

			backup_calib {
				reg = <0x414 0x10>;
				linux,phandle = <0x24>;
				phandle = <0x24>;
			};
		};

		clock-controller@900000 {
			compatible = "qcom,gcc-apq8064";
			reg = <0x900000 0x4000>;
			nvmem-cells = <0x23 0x24>;
			nvmem-cell-names = "calib\0calib_backup";
			qcom,tsens-slopes = <0x498 0x498 0x482 0x498 0x457 0x46c 0x46c 0x4af 0x46c 0x4af 0x46c>;
			#clock-cells = <0x01>;
			#reset-cells = <0x01>;
			#thermal-sensor-cells = <0x01>;
			linux,phandle = <0x0d>;
			phandle = <0x0d>;
		};

		clock-controller@28000000 {
			compatible = "qcom,lcc-apq8064";
			reg = <0x28000000 0x1000>;
			#clock-cells = <0x01>;
			#reset-cells = <0x01>;
		};

		clock-controller@4000000 {
			compatible = "qcom,mmcc-apq8064";
			reg = <0x4000000 0x1000>;
			#clock-cells = <0x01>;
			#reset-cells = <0x01>;
			linux,phandle = <0x3f>;
			phandle = <0x3f>;
		};

		clock-controller@2011000 {
			compatible = "syscon";
			reg = <0x2011000 0x1000>;
			linux,phandle = <0x25>;
			phandle = <0x25>;
		};

		rpm@108000 {
			compatible = "qcom,rpm-apq8064";
			reg = <0x108000 0x1000>;
			qcom,ipc = <0x25 0x08 0x02>;
			interrupts = <0x00 0x13 0x01 0x00 0x15 0x01 0x00 0x16 0x01>;
			interrupt-names = "ack\0err\0wakeup";

			clock-controller {
				compatible = "qcom,rpmcc-apq8064\0qcom,rpmcc";
				#clock-cells = <0x01>;
				linux,phandle = <0x4b>;
				phandle = <0x4b>;
			};

			regulators {
				compatible = "qcom,rpm-pm8921-regulators";
				vin_lvs1_3_6-supply = <0x26>;
				vin_lvs2-supply = <0x27>;
				vin_lvs4_5_7-supply = <0x26>;
				vdd_l1_l2_l12_l18-supply = <0x26>;
				vdd_l24-supply = <0x27>;
				vdd_l25-supply = <0x27>;
				vdd_l26-supply = <0x28>;
				vdd_l27-supply = <0x28>;
				vdd_l28-supply = <0x28>;

				s1 {
					regulator-always-on;
					regulator-min-microvolt = <0x12b128>;
					regulator-max-microvolt = <0x12b128>;
					qcom,switch-mode-frequency = <0x30d400>;
					bias-pull-down;
					linux,phandle = <0x27>;
					phandle = <0x27>;
				};

				s2 {
				};

				s3 {
					regulator-min-microvolt = <0xf4240>;
					regulator-max-microvolt = <0x155cc0>;
					qcom,switch-mode-frequency = "\0I>";
					linux,phandle = <0x29>;
					phandle = <0x29>;
				};

				s4 {
					regulator-min-microvolt = <0x1b7740>;
					regulator-max-microvolt = <0x1b7740>;
					qcom,switch-mode-frequency = <0x30d400>;
					linux,phandle = <0x26>;
					phandle = <0x26>;
				};

				s7 {
					regulator-min-microvolt = <0x13d620>;
					regulator-max-microvolt = <0x13d620>;
					qcom,switch-mode-frequency = <0x30d400>;
					linux,phandle = <0x28>;
					phandle = <0x28>;
				};

				s8 {
				};

				l1 {
				};

				l2 {
					regulator-min-microvolt = <0x124f80>;
					regulator-max-microvolt = <0x124f80>;
					bias-pull-down;
					linux,phandle = <0x48>;
					phandle = <0x48>;
				};

				l3 {
					regulator-min-microvolt = <0x2e8a10>;
					regulator-max-microvolt = <0x325aa0>;
					bias-pull-down;
					linux,phandle = <0x2a>;
					phandle = <0x2a>;
				};

				l4 {
					regulator-min-microvolt = <0xf4240>;
					regulator-max-microvolt = <0x1b7740>;
					bias-pull-down;
					linux,phandle = <0x2b>;
					phandle = <0x2b>;
				};

				l5 {
					regulator-min-microvolt = <0x29f630>;
					regulator-max-microvolt = <0x2dc6c0>;
					bias-pull-down;
					linux,phandle = <0x32>;
					phandle = <0x32>;
				};

				l6 {
					regulator-min-microvolt = <0x2d0370>;
					regulator-max-microvolt = <0x2d0370>;
					bias-pull-down;
					linux,phandle = <0x34>;
					phandle = <0x34>;
				};

				l7 {
				};

				l8 {
				};

				l9 {
				};

				l10 {
				};

				l11 {
				};

				l12 {
				};

				l14 {
				};

				l15 {
				};

				l16 {
				};

				l17 {
				};

				l18 {
				};

				l21 {
				};

				l22 {
				};

				l23 {
					regulator-min-microvolt = <0x19f0a0>;
					regulator-max-microvolt = <0x1cfde0>;
					bias-pull-down;
					linux,phandle = <0x2c>;
					phandle = <0x2c>;
				};

				l24 {
				};

				l25 {
				};

				l26 {
					regulator-min-microvolt = <0x5b8d8>;
					regulator-max-microvolt = <0x100590>;
					bias-pull-down;
					linux,phandle = <0x3d>;
					phandle = <0x3d>;
				};

				l27 {
				};

				l28 {
				};

				l29 {
				};

				lvs1 {
					bias-pull-down;
					linux,phandle = <0x39>;
					phandle = <0x39>;
				};

				lvs2 {
				};

				lvs3 {
				};

				lvs4 {
				};

				lvs5 {
				};

				lvs6 {
					bias-pull-down;
					linux,phandle = <0x3b>;
					phandle = <0x3b>;
				};

				lvs7 {
					bias-pull-down;
					linux,phandle = <0x49>;
					phandle = <0x49>;
				};

				usb-switch {
				};

				hdmi-switch {
					bias-pull-down;
					linux,phandle = <0x41>;
					phandle = <0x41>;
				};

				ncp {
				};
			};
		};

		phy@12500000 {
			compatible = "qcom,usb-otg-ci";
			reg = <0x12500000 0x400>;
			interrupts = <0x00 0x64 0x00>;
			status = "okay";
			dr_mode = "host";
			clocks = <0x0d 0x80 0x0d 0x7e>;
			clock-names = "core\0iface";
			resets = <0x0d 0x40>;
			reset-names = "link";
			vddcx-supply = <0x29>;
			v3p3-supply = <0x2a>;
			v1p8-supply = <0x2b>;
			linux,phandle = <0x2d>;
			phandle = <0x2d>;
		};

		phy@12520000 {
			compatible = "qcom,usb-otg-ci";
			reg = <0x12520000 0x400>;
			interrupts = <0x00 0xbc 0x00>;
			status = "okay";
			dr_mode = "host";
			clocks = <0x0d 0x129 0x0d 0x127>;
			clock-names = "core\0iface";
			resets = <0x0d 0x64>;
			reset-names = "link";
			vddcx-supply = <0x29>;
			v3p3-supply = <0x2a>;
			v1p8-supply = <0x2c>;
			linux,phandle = <0x2e>;
			phandle = <0x2e>;
		};

		phy@12530000 {
			compatible = "qcom,usb-otg-ci";
			reg = <0x12530000 0x400>;
			interrupts = <0x00 0xd7 0x00>;
			status = "okay";
			dr_mode = "host";
			clocks = <0x0d 0x12c 0x0d 0x12a>;
			clock-names = "core\0iface";
			resets = <0x0d 0x65>;
			reset-names = "link";
			vddcx-supply = <0x29>;
			v3p3-supply = <0x2a>;
			v1p8-supply = <0x2c>;
			linux,phandle = <0x2f>;
			phandle = <0x2f>;
		};

		gadget@12500000 {
			compatible = "qcom,ci-hdrc";
			reg = <0x12500000 0x400>;
			status = "okay";
			dr_mode = "peripheral";
			interrupts = <0x00 0x64 0x00>;
			usb-phy = <0x2d>;
		};

		usb@12500000 {
			compatible = "qcom,ehci-host";
			reg = <0x12500000 0x400>;
			interrupts = <0x00 0x64 0x00>;
			status = "okay";
			usb-phy = <0x2d>;
		};

		usb@12520000 {
			compatible = "qcom,ehci-host";
			reg = <0x12520000 0x400>;
			interrupts = <0x00 0xbc 0x00>;
			status = "okay";
			usb-phy = <0x2e>;
		};

		usb@12530000 {
			compatible = "qcom,ehci-host";
			reg = <0x12530000 0x400>;
			interrupts = <0x00 0xd7 0x00>;
			status = "okay";
			usb-phy = <0x2f>;
		};

		phy@1b400000 {
			compatible = "qcom,apq8064-sata-phy";
			status = "okay";
			reg = <0x1b400000 0x200>;
			reg-names = "phy_mem";
			clocks = <0x0d 0x12d>;
			clock-names = "cfg";
			#phy-cells = <0x00>;
			linux,phandle = <0x30>;
			phandle = <0x30>;
		};

		sata@29000000 {
			compatible = "generic-ahci";
			status = "okay";
			reg = <0x29000000 0x180>;
			interrupts = <0x00 0xd1 0x00>;
			clocks = <0x0d 0x3b 0x0d 0xed 0x0d 0x12e 0x0d 0xef 0x0d 0xf0>;
			clock-names = "slave_iface\0iface\0bus\0rxoob\0core_pmalive";
			assigned-clocks = <0x0d 0xef 0x0d 0xf0>;
			assigned-clock-rates = <0x5f5e100 0x5f5e100>;
			phys = <0x30>;
			phy-names = "sata-phy";
			target-supply = <0x26>;
		};

		dma@12402000 {
			compatible = "qcom,bam-v1.3.0";
			reg = <0x12402000 0x8000>;
			interrupts = <0x00 0x62 0x00>;
			clocks = <0x0d 0x6e>;
			clock-names = "bam_clk";
			#dma-cells = <0x01>;
			qcom,ee = <0x00>;
			linux,phandle = <0x31>;
			phandle = <0x31>;
		};

		dma@12182000 {
			compatible = "qcom,bam-v1.3.0";
			reg = <0x12182000 0x8000>;
			interrupts = <0x00 0x60 0x00>;
			clocks = <0x0d 0x70>;
			clock-names = "bam_clk";
			#dma-cells = <0x01>;
			qcom,ee = <0x00>;
			linux,phandle = <0x33>;
			phandle = <0x33>;
		};

		dma@121c2000 {
			compatible = "qcom,bam-v1.3.0";
			reg = <0x121c2000 0x8000>;
			interrupts = <0x00 0x5f 0x00>;
			clocks = <0x0d 0x71>;
			clock-names = "bam_clk";
			#dma-cells = <0x01>;
			qcom,ee = <0x00>;
			linux,phandle = <0x36>;
			phandle = <0x36>;
		};

		amba {
			compatible = "arm,amba-bus";
			#address-cells = <0x01>;
			#size-cells = <0x01>;
			ranges;

			sdcc@12400000 {
				status = "okay";
				compatible = "arm,pl18x\0arm,primecell";
				arm,primecell-periphid = <0x51180>;
				reg = <0x12400000 0x2000>;
				interrupts = <0x00 0x68 0x04>;
				interrupt-names = "cmd_irq";
				clocks = <0x0d 0x78 0x0d 0x6e>;
				clock-names = "mclk\0apb_pclk";
				bus-width = <0x08>;
				max-frequency = <0x5b8d800>;
				non-removable;
				cap-sd-highspeed;
				cap-mmc-highspeed;
				dmas = <0x31 0x02 0x31 0x01>;
				dma-names = "tx\0rx";
				vmmc-supply = <0x32>;
				vqmmc-supply = <0x26>;
			};

			sdcc@12180000 {
				compatible = "arm,pl18x\0arm,primecell";
				arm,primecell-periphid = <0x51180>;
				status = "okay";
				reg = <0x12180000 0x2000>;
				interrupts = <0x00 0x66 0x04>;
				interrupt-names = "cmd_irq";
				clocks = <0x0d 0x7a 0x0d 0x70>;
				clock-names = "mclk\0apb_pclk";
				bus-width = <0x04>;
				cap-sd-highspeed;
				cap-mmc-highspeed;
				max-frequency = <0xb71b000>;
				no-1-8-v;
				dmas = <0x33 0x02 0x33 0x01>;
				dma-names = "tx\0rx";
				vmmc-supply = <0x34>;
				pinctrl-names = "default";
				pinctrl-0 = <0x35>;
				cd-gpios = <0x21 0x1a 0x01>;
			};

			sdcc@121c0000 {
				compatible = "arm,pl18x\0arm,primecell";
				arm,primecell-periphid = <0x51180>;
				status = "okay";
				reg = <0x121c0000 0x2000>;
				interrupts = <0x00 0x65 0x04>;
				interrupt-names = "cmd_irq";
				clocks = <0x0d 0x7b 0x0d 0x71>;
				clock-names = "mclk\0apb_pclk";
				bus-width = <0x04>;
				cap-sd-highspeed;
				cap-mmc-highspeed;
				max-frequency = <0x2dc6c00>;
				dmas = <0x36 0x02 0x36 0x01>;
				dma-names = "tx\0rx";
				pinctrl-names = "default";
				pinctrl-0 = <0x37>;
				vmmc-supply = <0x38>;
				vqmmc-supply = <0x39>;
				mmc-pwrseq = <0x3a>;
			};
		};

		dma@18320000 {
			compatible = "qcom,adm";
			reg = <0x18320000 0xe0000>;
			interrupts = <0x00 0xab 0x00>;
			#dma-cells = <0x01>;
			clocks = <0x0d 0x26 0x0d 0x27>;
			clock-names = "core\0iface";
			resets = <0x0d 0x0f 0x0d 0x0e 0x0d 0x0d 0x0d 0x0c 0x0d 0x0b>;
			reset-names = "clk\0pbus\0c0\0c1\0c2";
			qcom,ee = <0x01>;
			status = "okay";
			linux,phandle = <0x1e>;
			phandle = <0x1e>;
		};

		syscon@1a400000 {
			compatible = "qcom,tcsr-apq8064\0syscon";
			reg = <0x1a400000 0x100>;
			linux,phandle = <0x1b>;
			phandle = <0x1b>;
		};

		pci@1b500000 {
			compatible = "qcom,pcie-apq8064\0snps,dw-pcie";
			reg = <0x1b500000 0x1000 0x1b502000 0x80 0x1b600000 0x100 0xff00000 0x100000>;
			reg-names = "dbi\0elbi\0parf\0config";
			device_type = "pci";
			linux,pci-domain = <0x00>;
			bus-range = <0x00 0xff>;
			num-lanes = <0x01>;
			#address-cells = <0x03>;
			#size-cells = <0x02>;
			ranges = <0x81000000 0x00 0x00 0xfe00000 0x00 0x100000 0x82000000 0x00 0x00 0x8000000 0x00 0x7e00000>;
			interrupts = <0x00 0xee 0x00>;
			interrupt-names = "msi";
			#interrupt-cells = <0x01>;
			interrupt-map-mask = <0x00 0x00 0x00 0x07>;
			interrupt-map = <0x00 0x00 0x00 0x01 0x01 0x00 0x24 0x04 0x00 0x00 0x00 0x02 0x01 0x00 0x25 0x04 0x00 0x00 0x00 0x03 0x01 0x00 0x26 0x04 0x00 0x00 0x00 0x04 0x01 0x00 0x27 0x04>;
			clocks = <0x0d 0x2b 0x0d 0x2e 0x0d 0x2d>;
			clock-names = "core\0iface\0phy";
			resets = <0x0d 0x6c 0x0d 0x6b 0x0d 0x6a 0x0d 0x69 0x0d 0x68>;
			reset-names = "axi\0ahb\0por\0pci\0phy";
			status = "ok";
			vdda-supply = <0x29>;
			vdda_phy-supply = <0x3b>;
			vdda_refclk-supply = <0x38>;
			pinctrl-0 = <0x3c>;
			pinctrl-names = "default";
			perst-gpio = <0x21 0x1b 0x01>;
		};

		pil@28800000 {
			compatible = "qcom,tz-pil\0qcom,apq8064-tz-pil";
			qcom,firmware-name = "q6";
			reg = <0x28800000 0x100>;
			reg-names = "qdsp6_base";
			qcom,pas-id = <0x01>;
			qcom,pll-supply = <0x3d>;
			qcom,pll-uV = <0x100590>;
			linux,phandle = <0x3e>;
			phandle = <0x3e>;
		};

		smd {
			compatible = "qcom,smd";

			adsp_a11 {
				interrupts = <0x00 0x5a 0x01>;
				qcom,ipc = <0x25 0x08 0x0f>;
				qcom,smd-edge = <0x01>;
				qcom,remote-pid = <0x02>;

				q6_requests {
					compatible = "qcom,apr";
					qcom,smd-channels = "apr_audio_svc";
					rproc = <0x3e>;
				};
			};
		};

		dai_fe {
			compatible = "qcom,msm-dai-fe";
			#sound-dai-cells = <0x00>;
		};

		dai_hdmi {
			compatible = "qcom,msm-dai-q6-hdmi";
			#sound-dai-cells = <0x00>;
		};

		codec_hdmi {
			compatible = "linux,hdmi-audio";
			#sound-dai-cells = <0x00>;
		};

		msm_pcm {
			compatible = "qcom,msm-pcm-dsp";
			#sound-dai-cells = <0x00>;
		};

		msm_pcm_routing {
			compatible = "qcom,msm-pcm-routing";
			#sound-dai-cells = <0x00>;
		};

		snd {
			compatible = "qcom,snd-apq8064";
		};

		qcom,hdmi-tx@4a00000 {
			compatible = "qcom,hdmi-tx-8960";
			reg-names = "core_physical";
			reg = <0x4a00000 0x1000>;
			interrupts = <0x00 0x4f 0x00>;
			clock-names = "core_clk\0master_iface_clk\0slave_iface_clk";
			clocks = <0x3f 0x3e 0x3f 0x0c 0x3f 0x15>;
			qcom,hdmi-tx-ddc-clk = <0x21 0x46 0x00>;
			qcom,hdmi-tx-ddc-data = <0x21 0x47 0x00>;
			qcom,hdmi-tx-hpd = <0x21 0x48 0x00>;
			pinctrl-names = "default";
			pinctrl-0 = <0x40>;
			status = "okay";
			core-vdda-supply = <0x41>;
			hdmi-mux-supply = <0x38>;
			linux,phandle = <0x44>;
			phandle = <0x44>;
		};

		qcom,adreno-3xx@4300000 {
			compatible = "qcom,adreno-3xx";
			reg = <0x4300000 0x20000>;
			reg-names = "kgsl_3d0_reg_memory";
			interrupts = <0x00 0x50 0x00>;
			interrupt-names = "kgsl_3d0_irq";
			clock-names = "core_clk\0iface_clk\0mem_clk\0mem_iface_clk";
			clocks = <0x3f 0x47 0x3f 0x16 0x3f 0x21 0x3f 0x13>;
			qcom,chipid = <0x3020002>;
			iommus = <0x42 0x00 0x01 0x02 0x03 0x04 0x05 0x06 0x07 0x08 0x09 0x0a 0x0b 0x0c 0x0d 0x0e 0x0f 0x42 0x10 0x11 0x12 0x13 0x14 0x15 0x16 0x17 0x18 0x19 0x1a 0x1b 0x1c 0x1d 0x1e 0x1f 0x43 0x00 0x01 0x02 0x03 0x04 0x05 0x06 0x07 0x08 0x09 0x0a 0x0b 0x0c 0x0d 0x0e 0x0f 0x43 0x10 0x11 0x12 0x13 0x14 0x15 0x16 0x17 0x18 0x19 0x1a 0x1b 0x1c 0x1d 0x1e 0x1f>;
			linux,phandle = <0x45>;
			phandle = <0x45>;

			qcom,gpu-pwrlevels {
				compatible = "qcom,gpu-pwrlevels";

				qcom,gpu-pwrlevel@0 {
					qcom,gpu-freq = <0x1ad27480>;
				};

				qcom,gpu-pwrlevel@1 {
					qcom,gpu-freq = <0x19bfcc0>;
				};
			};
		};

		qcom,mdp@5100000 {
			compatible = "qcom,mdp";
			reg = <0x5100000 0xf0000>;
			interrupts = <0x00 0x4b 0x00>;
			connectors = <0x44>;
			gpus = <0x45>;
			clock-names = "core_clk\0iface_clk\0lut_clk\0src_clk\0hdmi_clk\0mdp_clk\0mdp_axi_clk";
			clocks = <0x3f 0x4d 0x3f 0x10 0x3f 0x4e 0x3f 0x61 0x3f 0x5f 0x3f 0x60 0x3f 0x1e>;
			iommus = <0x46 0x00 0x02 0x47 0x00 0x02>;
			status = "okay";
			lvds-vccs-3p3v-supply = <0x38>;
			lvds-pll-vdda-supply = <0x48>;
			lvds-vdda-supply = <0x49>;

			port {

				endpoint {
					remote-endpoint = <0x4a>;
					linux,phandle = <0x60>;
					phandle = <0x60>;
				};
			};
		};

		qcom,iommu@7500000 {
			compatible = "qcom,iommu-v0";
			#iommu-cells = <0x02>;
			clock-names = "smmu_pclk\0iommu_clk";
			clocks = <0x3f 0x0b 0x3f 0x1e>;
			reg = <0x7500000 0x100000>;
			interrupts = <0x00 0x3f 0x00 0x00 0x40 0x00>;
			ncb = <0x02>;
			linux,phandle = <0x46>;
			phandle = <0x46>;
		};

		qcom,iommu@7600000 {
			compatible = "qcom,iommu";
			#iommu-cells = <0x02>;
			clock-names = "smmu_pclk\0iommu_clk";
			clocks = <0x3f 0x0b 0x3f 0x1e>;
			reg = <0x7600000 0x100000>;
			interrupts = <0x00 0x3d 0x00 0x00 0x3e 0x00>;
			ncb = <0x02>;
			linux,phandle = <0x47>;
			phandle = <0x47>;
		};

		qcom,iommu@7c00000 {
			compatible = "qcom,iommu-v0";
			#iommu-cells = <0x10>;
			clock-names = "smmu_pclk\0iommu_clk";
			clocks = <0x3f 0x0b 0x3f 0x21>;
			reg = <0x7c00000 0x100000>;
			interrupts = <0x00 0x45 0x00 0x00 0x46 0x00>;
			ncb = <0x03>;
			linux,phandle = <0x42>;
			phandle = <0x42>;
		};

		qcom,iommu@7d00000 {
			compatible = "qcom,iommu-v0";
			#iommu-cells = <0x10>;
			clock-names = "smmu_pclk\0iommu_clk";
			clocks = <0x3f 0x0b 0x3f 0x21>;
			reg = <0x7d00000 0x100000>;
			interrupts = <0x00 0xd2 0x00 0x00 0xd3 0x00>;
			ncb = <0x03>;
			linux,phandle = <0x43>;
			phandle = <0x43>;
		};

		etb@1a01000 {
			compatible = "coresight-etb10\0arm,primecell";
			reg = <0x1a01000 0x1000>;
			clocks = <0x4b 0x08>;
			clock-names = "apb_pclk";

			port {

				endpoint {
					slave-mode;
					remote-endpoint = <0x4c>;
					linux,phandle = <0x4e>;
					phandle = <0x4e>;
				};
			};
		};

		tpiu@1a03000 {
			compatible = "arm,coresight-tpiu\0arm,primecell";
			reg = <0x1a03000 0x1000>;
			clocks = <0x4b 0x08>;
			clock-names = "apb_pclk";

			port {

				endpoint {
					slave-mode;
					remote-endpoint = <0x4d>;
					linux,phandle = <0x4f>;
					phandle = <0x4f>;
				};
			};
		};

		replicator {
			compatible = "arm,coresight-replicator";
			clocks = <0x4b 0x08>;
			clock-names = "apb_pclk";

			ports {
				#address-cells = <0x01>;
				#size-cells = <0x00>;

				port@0 {
					reg = <0x00>;

					endpoint {
						remote-endpoint = <0x4e>;
						linux,phandle = <0x4c>;
						phandle = <0x4c>;
					};
				};

				port@1 {
					reg = <0x01>;

					endpoint {
						remote-endpoint = <0x4f>;
						linux,phandle = <0x4d>;
						phandle = <0x4d>;
					};
				};

				port@2 {
					reg = <0x00>;

					endpoint {
						slave-mode;
						remote-endpoint = <0x50>;
						linux,phandle = <0x55>;
						phandle = <0x55>;
					};
				};
			};
		};

		funnel@1a04000 {
			compatible = "arm,coresight-funnel\0arm,primecell";
			reg = <0x1a04000 0x1000>;
			clocks = <0x4b 0x08>;
			clock-names = "apb_pclk";

			ports {
				#address-cells = <0x01>;
				#size-cells = <0x00>;

				port@0 {
					reg = <0x00>;

					endpoint {
						slave-mode;
						remote-endpoint = <0x51>;
						linux,phandle = <0x56>;
						phandle = <0x56>;
					};
				};

				port@1 {
					reg = <0x01>;

					endpoint {
						slave-mode;
						remote-endpoint = <0x52>;
						linux,phandle = <0x57>;
						phandle = <0x57>;
					};
				};

				port@4 {
					reg = <0x04>;

					endpoint {
						slave-mode;
						remote-endpoint = <0x53>;
						linux,phandle = <0x58>;
						phandle = <0x58>;
					};
				};

				port@5 {
					reg = <0x05>;

					endpoint {
						slave-mode;
						remote-endpoint = <0x54>;
						linux,phandle = <0x59>;
						phandle = <0x59>;
					};
				};

				port@8 {
					reg = <0x00>;

					endpoint {
						remote-endpoint = <0x55>;
						linux,phandle = <0x50>;
						phandle = <0x50>;
					};
				};
			};
		};

		etm@1a1c000 {
			compatible = "arm,coresight-etm3x\0arm,primecell";
			reg = <0x1a1c000 0x1000>;
			clocks = <0x4b 0x08>;
			clock-names = "apb_pclk";
			cpu = <0x0f>;

			port {

				endpoint {
					remote-endpoint = <0x56>;
					linux,phandle = <0x51>;
					phandle = <0x51>;
				};
			};
		};

		etm@1a1d000 {
			compatible = "arm,coresight-etm3x\0arm,primecell";
			reg = <0x1a1d000 0x1000>;
			clocks = <0x4b 0x08>;
			clock-names = "apb_pclk";
			cpu = <0x11>;

			port {

				endpoint {
					remote-endpoint = <0x57>;
					linux,phandle = <0x52>;
					phandle = <0x52>;
				};
			};
		};

		etm@1a1e000 {
			compatible = "arm,coresight-etm3x\0arm,primecell";
			reg = <0x1a1e000 0x1000>;
			clocks = <0x4b 0x08>;
			clock-names = "apb_pclk";
			cpu = <0x13>;

			port {

				endpoint {
					remote-endpoint = <0x58>;
					linux,phandle = <0x53>;
					phandle = <0x53>;
				};
			};
		};

		etm@1a1f000 {
			compatible = "arm,coresight-etm3x\0arm,primecell";
			reg = <0x1a1f000 0x1000>;
			clocks = <0x4b 0x08>;
			clock-names = "apb_pclk";
			cpu = <0x15>;

			port {

				endpoint {
					remote-endpoint = <0x59>;
					linux,phandle = <0x54>;
					phandle = <0x54>;
				};
			};
		};

		regulator-fixed@1 {
			compatible = "regulator-fixed";
			regulator-min-microvolt = <0x325aa0>;
			regulator-max-microvolt = <0x325aa0>;
			regulator-name = "ext_3p3v";
			regulator-type = "voltage";
			startup-delay-us = <0x00>;
			gpio = <0x21 0x4d 0x00>;
			enable-active-high;
			regulator-boot-on;
			linux,phandle = <0x38>;
			phandle = <0x38>;
		};

		panel_3p3v {
			compatible = "regulator-fixed";
			pinctrl-0 = <0x5a>;
			pinctrl-names = "default";
			regulator-min-microvolt = <0x325aa0>;
			regulator-max-microvolt = <0x325aa0>;
			regulator-name = "panel_en_3p3v";
			regulator-type = "voltage";
			startup-delay-us = <0x00>;
			gpio = <0x5b 0x24 0x00>;
			enable-active-high;
			regulator-boot-on;
			linux,phandle = <0x5f>;
			phandle = <0x5f>;
		};

		backlight {
			pinctrl-0 = <0x5c>;
			pinctrl-names = "default";
			compatible = "gpio-backlight";
			gpios = <0x5b 0x1a 0x00>;
			default-on;
			linux,phandle = <0x5e>;
			phandle = <0x5e>;
		};

		auo,b101xtn01 {
			status = "okay";
			compatible = "auo,b101xtn01";
			ddc-i2c-bus = <0x5d>;
			backlight = <0x5e>;
			power-supply = <0x5f>;

			port {

				endpoint {
					remote-endpoint = <0x60>;
					linux,phandle = <0x4a>;
					phandle = <0x4a>;
				};
			};
		};
	};

	pwrseq {
		compatible = "simple-bus";

		sdcc4_pwrseq {
			pinctrl-names = "default";
			pinctrl-0 = <0x61 0x62>;
			compatible = "mmc-pwrseq-simple";
			reset-gpios = <0x5b 0x2b 0x01 0x5b 0x2c 0x01>;
			linux,phandle = <0x3a>;
			phandle = <0x3a>;
		};
	};

	leds {
		compatible = "gpio-leds";
		pinctrl-names = "default";
		pinctrl-0 = <0x63>;

		led@1 {
			label = "apq8064:green:user1";
			gpios = <0x5b 0x12 0x00>;
			default-state = "on";
		};
	};
};
